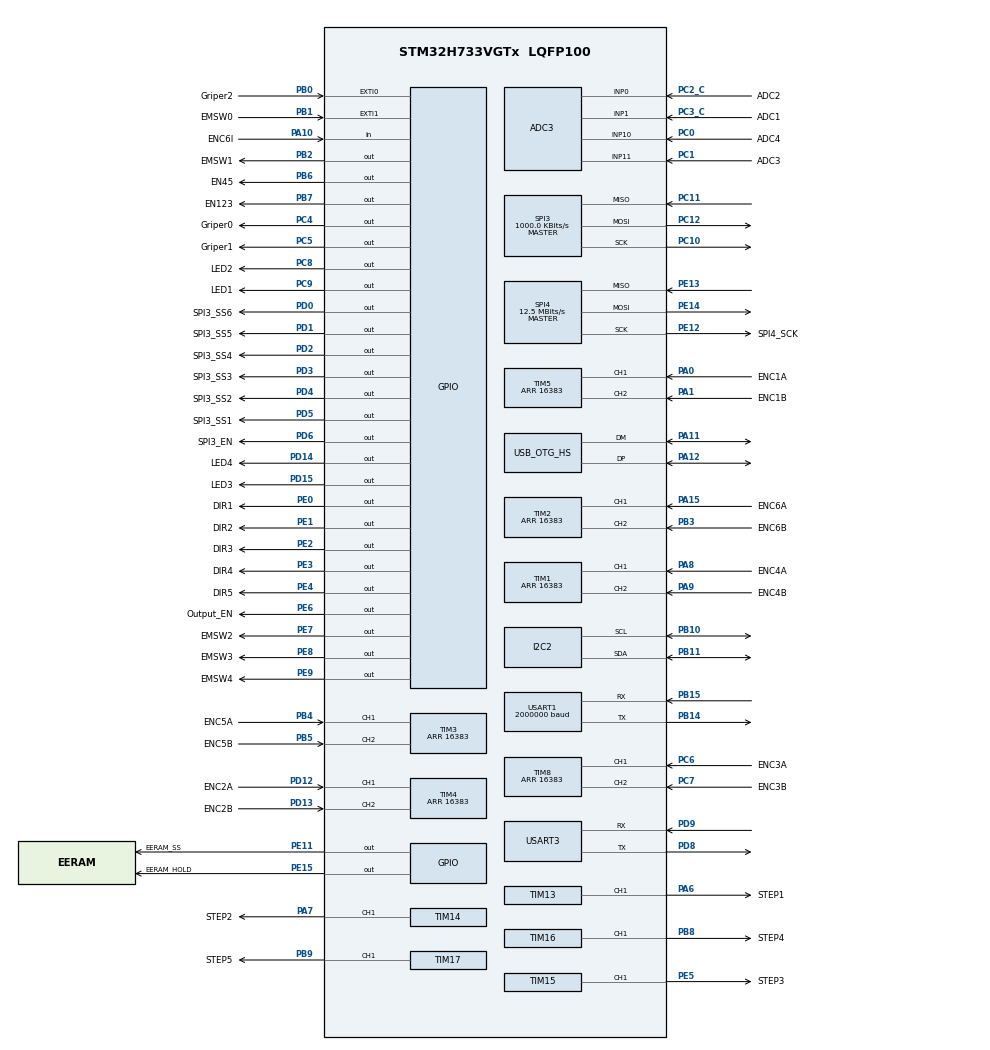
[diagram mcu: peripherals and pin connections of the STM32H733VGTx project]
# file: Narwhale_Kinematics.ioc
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ADC3.Channel-0\#ChannelRegularConversion=ADC_CHANNEL_TEMPSENSOR
ADC3.ClockPrescaler=ADC_CLOCK_ASYNC_DIV6
ADC3.ContinuousConvMode=ENABLE
ADC3.DMAContinuousRequests=DISABLE
ADC3.NbrOfConversion=1
ADC3.NbrOfConversionFlag=1
ADC3.OffsetNumber-0\#ChannelRegularConversion=ADC_OFFSET_NONE
ADC3.OffsetSaturation-0\#ChannelRegularConversion=DISABLE
ADC3.OffsetSign-0\#ChannelRegularConversion=ADC3_OFFSET_SIGN_NEGATIVE
ADC3.OffsetSignedSaturation-0\#ChannelRegularConversion=DISABLE
ADC3.Rank-0\#ChannelRegularConversion=1
ADC3.SamplingTime-0\#ChannelRegularConversion=ADC3_SAMPLETIME_247CYCLES_5
CRC.CRCLength=CRC_POLYLENGTH_8B
CRC.DefaultInitValueUse=DEFAULT_INIT_VALUE_DISABLE
CRC.DefaultPolynomialUse=DEFAULT_POLYNOMIAL_DISABLE
CRC.GeneratingPolynomial=X4+X3+X2+X0
CRC.InitValue=0xC4
CRC.InputDataFormat=CRC_INPUTDATA_FORMAT_HALFWORDS
Dma.Request0=USART1_RX
Dma.USART1_RX.0.Direction=DMA_PERIPH_TO_MEMORY
Dma.USART1_RX.0.EventEnable=DISABLE
Dma.USART1_RX.0.FIFOMode=DMA_FIFOMODE_DISABLE
Dma.USART1_RX.0.Instance=DMA1_Stream0
Dma.USART1_RX.0.MemDataAlignment=DMA_MDATAALIGN_BYTE
Dma.USART1_RX.0.MemInc=DMA_MINC_ENABLE
Dma.USART1_RX.0.Mode=DMA_CIRCULAR
Dma.USART1_RX.0.PeriphDataAlignment=DMA_PDATAALIGN_BYTE
Dma.USART1_RX.0.PeriphInc=DMA_PINC_DISABLE
Dma.USART1_RX.0.Polarity=HAL_DMAMUX_REQ_GEN_RISING
Dma.USART1_RX.0.Priority=DMA_PRIORITY_LOW
Dma.USART1_RX.0.RequestNumber=1
Dma.USART1_RX.0.SignalID=NONE
Dma.USART1_RX.0.SyncEnable=DISABLE
Dma.USART1_RX.0.SyncPolarity=HAL_DMAMUX_SYNC_NO_EVENT
Dma.USART1_RX.0.SyncRequestNumber=1
Dma.USART1_RX.0.SyncSignalID=NONE
I2C2.Timing=0x60404E72
Mcu.Family=STM32H7
Mcu.Name=STM32H733VGTx
Mcu.Package=LQFP100
NVIC.ADC3_IRQn=true\:0\:0\:false\:false\:true\:true\:true
NVIC.DMA1_Stream0_IRQn=true\:0\:0\:false\:false\:true\:false\:true
NVIC.OTG_HS_IRQn=true\:0\:0\:false\:false\:true\:false\:true
NVIC.PriorityGroup=NVIC_PRIORITYGROUP_4
PA0.GPIO_Label=ENC1A
PA0.Signal=S_TIM5_CH1
PA1.GPIO_Label=ENC1B
PA1.Signal=S_TIM5_CH2
PA10.GPIO_Label=ENC6I
PA10.Signal=GPIO_Input
PA11.Mode=Device_Only_FS
PA11.Signal=USB_OTG_HS_DM
PA12.Mode=Device_Only_FS
PA12.Signal=USB_OTG_HS_DP
PA13(JTMS/SWDIO).Mode=Serial_Wire
PA13(JTMS/SWDIO).Signal=DEBUG_JTMS-SWDIO
PA14(JTCK/SWCLK).Mode=Serial_Wire
PA14(JTCK/SWCLK).Signal=DEBUG_JTCK-SWCLK
PA15(JTDI).GPIO_Label=ENC6A
PA15(JTDI).Signal=S_TIM2_CH1_ETR
PA6.GPIO_Label=STEP1
PA6.Signal=S_TIM13_CH1
PA7.GPIO_Label=STEP2
PA7.Signal=S_TIM14_CH1
PA8.GPIO_Label=ENC4A
PA8.Signal=S_TIM1_CH1
PA9.GPIO_Label=ENC4B
PA9.Signal=S_TIM1_CH2
PB0.GPIO_Label=Griper2
PB0.Signal=GPXTI0
PB1.GPIO_Label=EMSW0
PB1.Signal=GPXTI1
PB10.GPIO_Pu=GPIO_PULLUP
PB10.Mode=I2C
PB10.Signal=I2C2_SCL
PB11.GPIO_Pu=GPIO_PULLUP
PB11.Mode=I2C
PB11.Signal=I2C2_SDA
PB14.Mode=Asynchronous
PB14.Signal=USART1_TX
PB15.Mode=Asynchronous
PB15.Signal=USART1_RX
PB2.GPIO_Label=EMSW1
PB2.Signal=GPIO_Output
PB3(JTDO/TRACESWO).GPIO_Label=ENC6B
PB3(JTDO/TRACESWO).Signal=S_TIM2_CH2
PB4(NJTRST).GPIO_Label=ENC5A
PB4(NJTRST).Signal=S_TIM3_CH1
PB5.GPIO_Label=ENC5B
PB5.Signal=S_TIM3_CH2
PB6.GPIO_Label=EN45
PB6.Signal=GPIO_Output
PB7.GPIO_Label=EN123
PB7.Signal=GPIO_Output
PB8.GPIO_Label=STEP4
PB8.Signal=S_TIM16_CH1
PB9.GPIO_Label=STEP5
PB9.Signal=S_TIM17_CH1
PC0.GPIO_Label=ADC4
PC0.Signal=ADCx_INP10
PC1.GPIO_Label=ADC3
PC1.Signal=ADCx_INP11
PC10.Mode=Full_Duplex_Master
PC10.Signal=SPI3_SCK
PC11.Mode=Full_Duplex_Master
PC11.Signal=SPI3_MISO
PC12.Mode=Full_Duplex_Master
PC12.Signal=SPI3_MOSI
PC2_C.GPIO_Label=ADC2
PC2_C.Mode=IN0-Single-Ended
PC2_C.Signal=ADC3_INP0
PC3_C.GPIO_Label=ADC1
PC3_C.Mode=IN1-Single-Ended
PC3_C.Signal=ADC3_INP1
PC4.GPIO_Label=Griper0
PC4.Signal=GPIO_Output
PC5.GPIO_Label=Griper1
PC5.Signal=GPIO_Output
PC6.GPIO_Label=ENC3A
PC6.Signal=S_TIM8_CH1
PC7.GPIO_Label=ENC3B
PC7.Signal=S_TIM8_CH2
PC8.GPIO_Label=LED2
PC8.PinState=GPIO_PIN_RESET
PC8.Signal=GPIO_Output
PC9.GPIO_Label=LED1
PC9.PinState=GPIO_PIN_RESET
PC9.Signal=GPIO_Output
PD0.GPIO_Label=SPI3_SS6
PD0.PinState=GPIO_PIN_SET
PD0.Signal=GPIO_Output
PD1.GPIO_Label=SPI3_SS5
PD1.PinState=GPIO_PIN_SET
PD1.Signal=GPIO_Output
PD12.GPIO_Label=ENC2A
PD12.Signal=S_TIM4_CH1
PD13.GPIO_Label=ENC2B
PD13.Signal=S_TIM4_CH2
PD14.GPIO_Label=LED4
PD14.Signal=GPIO_Output
PD15.GPIO_Label=LED3
PD15.Signal=GPIO_Output
PD2.GPIO_Label=SPI3_SS4
PD2.PinState=GPIO_PIN_SET
PD2.Signal=GPIO_Output
PD3.GPIO_Label=SPI3_SS3
PD3.PinState=GPIO_PIN_SET
PD3.Signal=GPIO_Output
PD4.GPIO_Label=SPI3_SS2
PD4.PinState=GPIO_PIN_SET
PD4.Signal=GPIO_Output
PD5.GPIO_Label=SPI3_SS1
PD5.PinState=GPIO_PIN_SET
PD5.Signal=GPIO_Output
PD6.GPIO_Label=SPI3_EN
PD6.Signal=GPIO_Output
PD8.Mode=Asynchronous
PD8.Signal=USART3_TX
PD9.Mode=Asynchronous
PD9.Signal=USART3_RX
PE0.GPIO_Label=DIR1
PE0.Signal=GPIO_Output
PE1.GPIO_Label=DIR2
PE1.Signal=GPIO_Output
PE11.GPIO_Label=EERAM_SS
PE11.Signal=GPIO_Output
PE12.GPIO_Label=SPI4_SCK
PE12.Mode=Full_Duplex_Master
PE12.Signal=SPI4_SCK
PE13.Mode=Full_Duplex_Master
PE13.Signal=SPI4_MISO
PE14.Mode=Full_Duplex_Master
PE14.Signal=SPI4_MOSI
PE15.GPIO_Label=EERAM_HOLD
PE15.Signal=GPIO_Output
PE2.GPIO_Label=DIR3
PE2.Signal=GPIO_Output
PE3.GPIO_Label=DIR4
PE3.Signal=GPIO_Output
PE4.GPIO_Label=DIR5
PE4.Signal=GPIO_Output
PE5.GPIO_Label=STEP3
PE5.Signal=S_TIM15_CH1
PE6.GPIO_Label=Output_EN
PE6.Signal=GPIO_Output
PE7.GPIO_Label=EMSW2
PE7.Signal=GPIO_Output
PE8.GPIO_Label=EMSW3
PE8.Signal=GPIO_Output
PE9.GPIO_Label=EMSW4
PE9.Signal=GPIO_Output
PH0-OSC_IN.Mode=HSE-External-Oscillator
PH0-OSC_IN.Signal=RCC_OSC_IN
PH1-OSC_OUT.Mode=HSE-External-Oscillator
PH1-OSC_OUT.Signal=RCC_OSC_OUT
ProjectManager.HeapSize=0x200
ProjectManager.StackSize=0x400
ProjectManager.TargetToolchain=STM32CubeIDE
RCC.ADCFreq_Value=100000000
RCC.APB1Freq_Value=137500000
RCC.APB2Freq_Value=137500000
RCC.APB3Freq_Value=137500000
RCC.APB4Freq_Value=137500000
RCC.CortexFreq_Value=550000000
RCC.D1PPRE=RCC_APB3_DIV2
RCC.D2PPRE1=RCC_APB1_DIV2
RCC.D2PPRE2=RCC_APB2_DIV2
RCC.D3PPRE=RCC_APB4_DIV2
RCC.DIVM1=2
RCC.DIVM2=2
RCC.DIVM3=25
RCC.DIVN1=44
RCC.DIVN2=16
RCC.DIVN3=256
RCC.DIVP1=1
RCC.HCLKFreq_Value=275000000
RCC.HPRE=RCC_HCLK_DIV2
RCC.LockedElements=D1CPREOutput
RCC.PLL1_VCI_Range-AdvancedSettings=RCC_PLL1VCIRANGE_0
RCC.PLL1_VCO_SEL-AdvancedSettings=RCC_PLL1VCOWIDE
RCC.PLL2_VCI_Range-AdvancedSettings=RCC_PLL2VCIRANGE_0
RCC.PLL2_VCO_SEL-AdvancedSettings=RCC_PLL2VCOMEDIUM
RCC.PLL3_VCI_Range-AdvancedSettings=RCC_PLL3VCIRANGE_3
RCC.PLL3_VCO_SEL-AdvancedSettings=RCC_PLL3VCOWIDE
RCC.PLLSourceVirtual=RCC_PLLSOURCE_HSE
RCC.SPI123CLockSelection=RCC_SPI123CLKSOURCE_PLL3
RCC.SYSCLKFreq_VALUE=550000000
RCC.SYSCLKSource=RCC_SYSCLKSOURCE_PLLCLK
RCC.Spi45ClockSelection=RCC_SPI45CLKSOURCE_PLL2
RCC.USART16CLockSelection=RCC_USART16910CLKSOURCE_PLL2
RCC.USART234578CLockSelection=RCC_USART234578CLKSOURCE_PLL2
RCC.USBCLockSelection=RCC_USBCLKSOURCE_HSI48
RCC.USBFreq_Value=48000000
SH.ADCx_INP10.0=ADC3_INP10,IN10-Single-Ended
SH.ADCx_INP11.0=ADC3_INP11,IN11-Single-Ended
SH.S_TIM13_CH1.0=TIM13_CH1,PWM Generation1 CH1
SH.S_TIM14_CH1.0=TIM14_CH1,PWM Generation1 CH1
SH.S_TIM15_CH1.0=TIM15_CH1,PWM Generation1 CH1
SH.S_TIM16_CH1.0=TIM16_CH1,PWM Generation1 CH1
SH.S_TIM17_CH1.0=TIM17_CH1,PWM Generation1 CH1
SH.S_TIM1_CH1.0=TIM1_CH1,Encoder_Interface
SH.S_TIM1_CH2.0=TIM1_CH2,Encoder_Interface
SH.S_TIM2_CH1_ETR.0=TIM2_CH1,Encoder_Interface
SH.S_TIM2_CH2.0=TIM2_CH2,Encoder_Interface
SH.S_TIM3_CH1.0=TIM3_CH1,Encoder_Interface
SH.S_TIM3_CH2.0=TIM3_CH2,Encoder_Interface
SH.S_TIM4_CH1.0=TIM4_CH1,Encoder_Interface
SH.S_TIM4_CH2.0=TIM4_CH2,Encoder_Interface
SH.S_TIM5_CH1.0=TIM5_CH1,Encoder_Interface
SH.S_TIM5_CH2.0=TIM5_CH2,Encoder_Interface
SH.S_TIM8_CH1.0=TIM8_CH1,Encoder_Interface
SH.S_TIM8_CH2.0=TIM8_CH2,Encoder_Interface
SPI3.BaudRatePrescaler=SPI_BAUDRATEPRESCALER_128
SPI3.CLKPhase=SPI_PHASE_2EDGE
SPI3.CRCCalculation=SPI_CRCCALCULATION_DISABLE
SPI3.CRCPolynomial=0x1D
SPI3.CalculateBaudRate=1000.0 KBits/s
SPI3.DataSize=SPI_DATASIZE_8BIT
SPI3.Direction=SPI_DIRECTION_2LINES
SPI3.FirstBit=SPI_FIRSTBIT_MSB
SPI3.Mode=SPI_MODE_MASTER
SPI3.VirtualType=VM_MASTER
SPI4.BaudRatePrescaler=SPI_BAUDRATEPRESCALER_8
SPI4.CalculateBaudRate=12.5 MBits/s
SPI4.DataSize=SPI_DATASIZE_16BIT
SPI4.Direction=SPI_DIRECTION_2LINES
SPI4.Mode=SPI_MODE_MASTER
SPI4.VirtualType=VM_MASTER
TIM1.AutoReloadPreload=TIM_AUTORELOAD_PRELOAD_ENABLE
TIM1.EncoderMode=TIM_ENCODERMODE_TI12
TIM1.IC1Filter=0
TIM1.IC2Filter=0
TIM1.Period=16383
TIM13.Channel=TIM_CHANNEL_1
TIM13.Period=1000-1
TIM13.Prescaler=275-1
TIM13.Pulse=500-1
TIM14.Channel=TIM_CHANNEL_1
TIM14.Period=1000-1
TIM14.Prescaler=275-1
TIM14.Pulse=500-1
TIM15.Channel-PWM\ Generation1\ CH1=TIM_CHANNEL_1
TIM15.Period=20000-1
TIM15.Prescaler=275-1
TIM15.Pulse-PWM\ Generation1\ CH1=2000-1
TIM16.Channel=TIM_CHANNEL_1
TIM16.Period=1000-1
TIM16.Prescaler=275-1
TIM16.Pulse=500-1
TIM17.Channel=TIM_CHANNEL_1
TIM17.Period=1000-1
TIM17.Prescaler=275-1
TIM17.Pulse=500-1
TIM2.AutoReloadPreload=TIM_AUTORELOAD_PRELOAD_ENABLE
TIM2.EncoderMode=TIM_ENCODERMODE_TI12
TIM2.IC1Filter=0
TIM2.IC2Filter=0
TIM2.Period=16383
TIM23.Prescaler=275-1
TIM24.Prescaler=275-1
TIM3.AutoReloadPreload=TIM_AUTORELOAD_PRELOAD_ENABLE
TIM3.EncoderMode=TIM_ENCODERMODE_TI12
TIM3.IC1Filter=0
TIM3.IC2Filter=10
TIM3.Period=16383
TIM4.AutoReloadPreload=TIM_AUTORELOAD_PRELOAD_ENABLE
TIM4.EncoderMode=TIM_ENCODERMODE_TI12
TIM4.IC1Filter=0
TIM4.IC2Filter=0
TIM4.Period=16383
TIM5.AutoReloadPreload=TIM_AUTORELOAD_PRELOAD_ENABLE
TIM5.EncoderMode=TIM_ENCODERMODE_TI12
TIM5.IC1Filter=0
TIM5.IC2Filter=0
TIM5.Period=16383
TIM5.TIM_MasterOutputTrigger=TIM_TRGO_RESET
TIM6.Prescaler=275-1
TIM8.AutoReloadPreload=TIM_AUTORELOAD_PRELOAD_ENABLE
TIM8.EncoderMode=TIM_ENCODERMODE_TI12
TIM8.IC1Filter=0
TIM8.IC2Filter=0
TIM8.Period=16383
USART1.BaudRate=2000000
USART1.SwapParam=ADVFEATURE_SWAP_DISABLE
USART1.VirtualMode-Asynchronous=VM_ASYNC
USART3.VirtualMode-Asynchronous=VM_ASYNC
USB_DEVICE.CLASS_NAME_HS=CDC
USB_DEVICE.VirtualMode=Cdc
USB_DEVICE.VirtualModeHS=Cdc_HS
USB_OTG_HS.VirtualMode-Device_Only_FS=Device_Only_FS
VP_ADC3_TempSens_Input.Mode=IN-TempSens
VP_ADC3_Vbat_Input.Mode=IN-Vbat
VP_CRC_VS_CRC.Mode=CRC_Activate
VP_TIM13_VS_ClockSourceINT.Mode=Enable_Timer
VP_TIM14_VS_ClockSourceINT.Mode=Enable_Timer
VP_TIM16_VS_ClockSourceINT.Mode=Enable_Timer
VP_TIM17_VS_ClockSourceINT.Mode=Enable_Timer
VP_TIM23_VS_ClockSourceINT.Mode=Internal
VP_TIM24_VS_ClockSourceINT.Mode=Internal
VP_TIM6_VS_ClockSourceINT.Mode=Enable_Timer
VP_USB_DEVICE_VS_USB_DEVICE_CDC_HS.Mode=CDC_HS
board=custom

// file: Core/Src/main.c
/* USER CODE BEGIN Header */
/**
  ******************************************************************************
  * @file           : main.c
  * @brief          : Main program body
  ******************************************************************************
  * @attention
  *
  * Copyright (c) 2022 STMicroelectronics.
  * All rights reserved.
  *
  * This software is licensed under terms that can be found in the LICENSE file
  * in the root directory of this software component.
  * If no LICENSE file comes with this software, it is provided AS-IS.
  *
  ******************************************************************************
  */
/* USER CODE END Header */
#include "main.h"
#include "usb_device.h"
#include "kinematics.h"

/* USER CODE BEGIN PD */
//	float v_x[2] = {400.01,500};
//	float v_y[2]= {0,0};
//	float v_z[2] = {420.99,260};
//	float v_pitch[2] = {-3.1416,-3.1416};
//	float v_yaw[2] = {3.1416,3.1416};
	float q[5]={0,-0.6975,0.5554,0.1421,0};
	float qv[5];
	float v_x, v_y, v_z, v_pitch, v_yaw;

/* USER CODE END PD */

ADC_HandleTypeDef hadc3;

CRC_HandleTypeDef hcrc;

I2C_HandleTypeDef hi2c2;

SPI_HandleTypeDef hspi3;
SPI_HandleTypeDef hspi4;

TIM_HandleTypeDef htim1;
TIM_HandleTypeDef htim2;
TIM_HandleTypeDef htim3;
TIM_HandleTypeDef htim4;
TIM_HandleTypeDef htim5;
TIM_HandleTypeDef htim6;
TIM_HandleTypeDef htim8;
TIM_HandleTypeDef htim13;
TIM_HandleTypeDef htim14;
TIM_HandleTypeDef htim15;
TIM_HandleTypeDef htim16;
TIM_HandleTypeDef htim17;
TIM_HandleTypeDef htim23;
TIM_HandleTypeDef htim24;

UART_HandleTypeDef huart1;
UART_HandleTypeDef huart3;
DMA_HandleTypeDef hdma_usart1_rx;

void SystemClock_Config(void);
void PeriphCommonClock_Config(void);
static void MX_GPIO_Init(void);
static void MX_DMA_Init(void);
static void MX_ADC3_Init(void);
static void MX_TIM1_Init(void);
static void MX_TIM3_Init(void);
static void MX_TIM4_Init(void);
static void MX_TIM5_Init(void);
static void MX_TIM8_Init(void);
static void MX_TIM13_Init(void);
static void MX_TIM14_Init(void);
static void MX_TIM15_Init(void);
static void MX_TIM16_Init(void);
static void MX_TIM17_Init(void);
static void MX_USART1_UART_Init(void);
static void MX_USART3_UART_Init(void);
static void MX_SPI3_Init(void);
static void MX_SPI4_Init(void);
static void MX_TIM2_Init(void);
static void MX_I2C2_Init(void);
static void MX_CRC_Init(void);
static void MX_TIM24_Init(void);
static void MX_TIM23_Init(void);
static void MX_TIM6_Init(void);

int main(void)
{
  /* USER CODE BEGIN 1 */
	uint32_t timer1;
	v_x = 0.000023997;
	v_y = 0;
	v_z = -0.000038637;
	v_pitch = 0;
	v_yaw = 0;

  /* USER CODE END 1 */

  /* MCU Configuration--------------------------------------------------------*/

  /* Reset of all peripherals, Initializes the Flash interface and the Systick. */
  HAL_Init();

  /* Configure the system clock */
  SystemClock_Config();

/* Configure the peripherals common clocks */
  PeriphCommonClock_Config();

  /* Initialize all configured peripherals */
  MX_GPIO_Init();
  MX_DMA_Init();
  MX_ADC3_Init();
  MX_TIM1_Init();
  MX_TIM3_Init();
  MX_TIM4_Init();
  MX_TIM5_Init();
  MX_TIM8_Init();
  MX_TIM13_Init();
  MX_TIM14_Init();
  MX_TIM15_Init();
  MX_TIM16_Init();
  MX_TIM17_Init();
  MX_USART1_UART_Init();
  MX_USART3_UART_Init();
  MX_SPI3_Init();
  MX_SPI4_Init();
  MX_TIM2_Init();
  MX_I2C2_Init();
  MX_CRC_Init();
  MX_USB_DEVICE_Init();
  MX_TIM24_Init();
  MX_TIM23_Init();
  MX_TIM6_Init();

  /* Infinite loop */
	while (1) {

    /* USER CODE BEGIN 3 */
//		if (HAL_GetTick() - timer1 > 1000) { gettick จะนับไปเรื่อย
//			timer1 = HAL_GetTick(); keep count ตอนนั้นไว้ที่ timer1
//			HAL_GPIO_TogglePin(GPIOC, GPIO_PIN_9);
//		}
//		float a = cos(3.14);
		IVK(v_x, v_y, v_z, v_pitch, v_yaw, q, qv);

  }
  /* USER CODE END 3 */
}

void SystemClock_Config(void)
{
  RCC_OscInitTypeDef RCC_OscInitStruct = {0};
  RCC_ClkInitTypeDef RCC_ClkInitStruct = {0};

  /** Supply configuration update enable
  */
  HAL_PWREx_ConfigSupply(PWR_LDO_SUPPLY);
  /** Configure the main internal regulator output voltage
  */
  __HAL_PWR_VOLTAGESCALING_CONFIG(PWR_REGULATOR_VOLTAGE_SCALE0);

  while(!__HAL_PWR_GET_FLAG(PWR_FLAG_VOSRDY)) {}
  /** Macro to configure the PLL clock source
  */
  __HAL_RCC_PLL_PLLSOURCE_CONFIG(RCC_PLLSOURCE_HSE);
  /** Initializes the RCC Oscillators according to the specified parameters
  * in the RCC_OscInitTypeDef structure.
  */
  RCC_OscInitStruct.OscillatorType = RCC_OSCILLATORTYPE_HSI48|RCC_OSCILLATORTYPE_HSE;
  RCC_OscInitStruct.HSEState = RCC_HSE_ON;
  RCC_OscInitStruct.HSI48State = RCC_HSI48_ON;
  RCC_OscInitStruct.PLL.PLLState = RCC_PLL_ON;
  RCC_OscInitStruct.PLL.PLLSource = RCC_PLLSOURCE_HSE;
  RCC_OscInitStruct.PLL.PLLM = 2;
  RCC_OscInitStruct.PLL.PLLN = 44;
  RCC_OscInitStruct.PLL.PLLP = 1;
  RCC_OscInitStruct.PLL.PLLQ = 2;
  RCC_OscInitStruct.PLL.PLLR = 2;
  RCC_OscInitStruct.PLL.PLLRGE = RCC_PLL1VCIRANGE_3;
  RCC_OscInitStruct.PLL.PLLVCOSEL = RCC_PLL1VCOWIDE;
  RCC_OscInitStruct.PLL.PLLFRACN = 0;
  if (HAL_RCC_OscConfig(&RCC_OscInitStruct) != HAL_OK)
  {
    Error_Handler();
  }
  /** Initializes the CPU, AHB and APB buses clocks
  */
  RCC_ClkInitStruct.ClockType = RCC_CLOCKTYPE_HCLK|RCC_CLOCKTYPE_SYSCLK
                              |RCC_CLOCKTYPE_PCLK1|RCC_CLOCKTYPE_PCLK2
                              |RCC_CLOCKTYPE_D3PCLK1|RCC_CLOCKTYPE_D1PCLK1;
  RCC_ClkInitStruct.SYSCLKSource = RCC_SYSCLKSOURCE_PLLCLK;
  RCC_ClkInitStruct.SYSCLKDivider = RCC_SYSCLK_DIV1;
  RCC_ClkInitStruct.AHBCLKDivider = RCC_HCLK_DIV2;
  RCC_ClkInitStruct.APB3CLKDivider = RCC_APB3_DIV2;
  RCC_ClkInitStruct.APB1CLKDivider = RCC_APB1_DIV2;
  RCC_ClkInitStruct.APB2CLKDivider = RCC_APB2_DIV2;
  RCC_ClkInitStruct.APB4CLKDivider = RCC_APB4_DIV2;

  if (HAL_RCC_ClockConfig(&RCC_ClkInitStruct, FLASH_LATENCY_3) != HAL_OK)
  {
    Error_Handler();
  }
}

void PeriphCommonClock_Config(void)
{
  RCC_PeriphCLKInitTypeDef PeriphClkInitStruct = {0};

  /** Initializes the peripherals clock
  */
  PeriphClkInitStruct.PeriphClockSelection = RCC_PERIPHCLK_ADC|RCC_PERIPHCLK_SPI4
                              |RCC_PERIPHCLK_USART1|RCC_PERIPHCLK_USART3;
  PeriphClkInitStruct.PLL2.PLL2M = 2;
  PeriphClkInitStruct.PLL2.PLL2N = 16;
  PeriphClkInitStruct.PLL2.PLL2P = 2;
  PeriphClkInitStruct.PLL2.PLL2Q = 2;
  PeriphClkInitStruct.PLL2.PLL2R = 2;
  PeriphClkInitStruct.PLL2.PLL2RGE = RCC_PLL2VCIRANGE_3;
  PeriphClkInitStruct.PLL2.PLL2VCOSEL = RCC_PLL2VCOWIDE;
  PeriphClkInitStruct.PLL2.PLL2FRACN = 0;
  PeriphClkInitStruct.Spi45ClockSelection = RCC_SPI45CLKSOURCE_PLL2;
  PeriphClkInitStruct.Usart234578ClockSelection = RCC_USART234578CLKSOURCE_PLL2;
  PeriphClkInitStruct.Usart16ClockSelection = RCC_USART16910CLKSOURCE_PLL2;
  PeriphClkInitStruct.AdcClockSelection = RCC_ADCCLKSOURCE_PLL2;
  if (HAL_RCCEx_PeriphCLKConfig(&PeriphClkInitStruct) != HAL_OK)
  {
    Error_Handler();
  }
}

static void MX_ADC3_Init(void)
{

  ADC_ChannelConfTypeDef sConfig = {0};

  /** Common config
  */
  hadc3.Instance = ADC3;
  hadc3.Init.ClockPrescaler = ADC_CLOCK_ASYNC_DIV6;
  hadc3.Init.DataAlign = ADC3_DATAALIGN_RIGHT;
  hadc3.Init.ScanConvMode = ADC_SCAN_DISABLE;
  hadc3.Init.EOCSelection = ADC_EOC_SINGLE_CONV;
  hadc3.Init.LowPowerAutoWait = DISABLE;
  hadc3.Init.ContinuousConvMode = ENABLE;
  hadc3.Init.NbrOfConversion = 1;
  hadc3.Init.DiscontinuousConvMode = DISABLE;
  hadc3.Init.ExternalTrigConv = ADC_SOFTWARE_START;
  hadc3.Init.ExternalTrigConvEdge = ADC_EXTERNALTRIGCONVEDGE_NONE;
  hadc3.Init.DMAContinuousRequests = DISABLE;
  hadc3.Init.SamplingMode = ADC_SAMPLING_MODE_NORMAL;
  hadc3.Init.ConversionDataManagement = ADC_CONVERSIONDATA_DR;
  hadc3.Init.Overrun = ADC_OVR_DATA_PRESERVED;
  hadc3.Init.LeftBitShift = ADC_LEFTBITSHIFT_NONE;
  hadc3.Init.OversamplingMode = DISABLE;
  if (HAL_ADC_Init(&hadc3) != HAL_OK)
  {
    Error_Handler();
  }
  /** Configure Regular Channel
  */
  sConfig.Channel = ADC_CHANNEL_TEMPSENSOR;
  sConfig.Rank = ADC_REGULAR_RANK_1;
  sConfig.SamplingTime = ADC3_SAMPLETIME_247CYCLES_5;
  sConfig.SingleDiff = ADC_SINGLE_ENDED;
  sConfig.OffsetNumber = ADC_OFFSET_NONE;
  sConfig.Offset = 0;
  sConfig.OffsetSignedSaturation = DISABLE;
  sConfig.OffsetSign = ADC3_OFFSET_SIGN_NEGATIVE;
  sConfig.OffsetSaturation = DISABLE;
  if (HAL_ADC_ConfigChannel(&hadc3, &sConfig) != HAL_OK)
  {
    Error_Handler();
  }

}

static void MX_CRC_Init(void)
{

  hcrc.Instance = CRC;
  hcrc.Init.DefaultPolynomialUse = DEFAULT_POLYNOMIAL_DISABLE;
  hcrc.Init.DefaultInitValueUse = DEFAULT_INIT_VALUE_DISABLE;
  hcrc.Init.GeneratingPolynomial = 29;
  hcrc.Init.CRCLength = CRC_POLYLENGTH_8B;
  hcrc.Init.InitValue = 0xC4;
  hcrc.Init.InputDataInversionMode = CRC_INPUTDATA_INVERSION_NONE;
  hcrc.Init.OutputDataInversionMode = CRC_OUTPUTDATA_INVERSION_DISABLE;
  hcrc.InputDataFormat = CRC_INPUTDATA_FORMAT_HALFWORDS;
  if (HAL_CRC_Init(&hcrc) != HAL_OK)
  {
    Error_Handler();
  }

}

static void MX_I2C2_Init(void)
{

  hi2c2.Instance = I2C2;
  hi2c2.Init.Timing = 0x60404E72;
  hi2c2.Init.OwnAddress1 = 0;
  hi2c2.Init.AddressingMode = I2C_ADDRESSINGMODE_7BIT;
  hi2c2.Init.DualAddressMode = I2C_DUALADDRESS_DISABLE;
  hi2c2.Init.OwnAddress2 = 0;
  hi2c2.Init.OwnAddress2Masks = I2C_OA2_NOMASK;
  hi2c2.Init.GeneralCallMode = I2C_GENERALCALL_DISABLE;
  hi2c2.Init.NoStretchMode = I2C_NOSTRETCH_DISABLE;
  if (HAL_I2C_Init(&hi2c2) != HAL_OK)
  {
    Error_Handler();
  }
  /** Configure Analogue filter
  */
  if (HAL_I2CEx_ConfigAnalogFilter(&hi2c2, I2C_ANALOGFILTER_ENABLE) != HAL_OK)
  {
    Error_Handler();
  }
  /** Configure Digital filter
  */
  if (HAL_I2CEx_ConfigDigitalFilter(&hi2c2, 0) != HAL_OK)
  {
    Error_Handler();
  }

}

static void MX_SPI3_Init(void)
{

  /* SPI3 parameter configuration*/
  hspi3.Instance = SPI3;
  hspi3.Init.Mode = SPI_MODE_MASTER;
  hspi3.Init.Direction = SPI_DIRECTION_2LINES;
  hspi3.Init.DataSize = SPI_DATASIZE_8BIT;
  hspi3.Init.CLKPolarity = SPI_POLARITY_LOW;
  hspi3.Init.CLKPhase = SPI_PHASE_2EDGE;
  hspi3.Init.NSS = SPI_NSS_SOFT;
  hspi3.Init.BaudRatePrescaler = SPI_BAUDRATEPRESCALER_128;
  hspi3.Init.FirstBit = SPI_FIRSTBIT_MSB;
  hspi3.Init.TIMode = SPI_TIMODE_DISABLE;
  hspi3.Init.CRCCalculation = SPI_CRCCALCULATION_DISABLE;
  hspi3.Init.CRCPolynomial = 0x1D;
  hspi3.Init.NSSPMode = SPI_NSS_PULSE_ENABLE;
  hspi3.Init.NSSPolarity = SPI_NSS_POLARITY_LOW;
  hspi3.Init.FifoThreshold = SPI_FIFO_THRESHOLD_01DATA;
  hspi3.Init.TxCRCInitializationPattern = SPI_CRC_INITIALIZATION_ALL_ZERO_PATTERN;
  hspi3.Init.RxCRCInitializationPattern = SPI_CRC_INITIALIZATION_ALL_ZERO_PATTERN;
  hspi3.Init.MasterSSIdleness = SPI_MASTER_SS_IDLENESS_00CYCLE;
  hspi3.Init.MasterInterDataIdleness = SPI_MASTER_INTERDATA_IDLENESS_00CYCLE;
  hspi3.Init.MasterReceiverAutoSusp = SPI_MASTER_RX_AUTOSUSP_DISABLE;
  hspi3.Init.MasterKeepIOState = SPI_MASTER_KEEP_IO_STATE_DISABLE;
  hspi3.Init.IOSwap = SPI_IO_SWAP_DISABLE;
  if (HAL_SPI_Init(&hspi3) != HAL_OK)
  {
    Error_Handler();
  }

}

static void MX_SPI4_Init(void)
{

  /* SPI4 parameter configuration*/
  hspi4.Instance = SPI4;
  hspi4.Init.Mode = SPI_MODE_MASTER;
  hspi4.Init.Direction = SPI_DIRECTION_2LINES;
  hspi4.Init.DataSize = SPI_DATASIZE_16BIT;
  hspi4.Init.CLKPolarity = SPI_POLARITY_LOW;
  hspi4.Init.CLKPhase = SPI_PHASE_1EDGE;
  hspi4.Init.NSS = SPI_NSS_SOFT;
  hspi4.Init.BaudRatePrescaler = SPI_BAUDRATEPRESCALER_8;
  hspi4.Init.FirstBit = SPI_FIRSTBIT_MSB;
  hspi4.Init.TIMode = SPI_TIMODE_DISABLE;
  hspi4.Init.CRCCalculation = SPI_CRCCALCULATION_DISABLE;
  hspi4.Init.CRCPolynomial = 0x0;
  hspi4.Init.NSSPMode = SPI_NSS_PULSE_ENABLE;
  hspi4.Init.NSSPolarity = SPI_NSS_POLARITY_LOW;
  hspi4.Init.FifoThreshold = SPI_FIFO_THRESHOLD_01DATA;
  hspi4.Init.TxCRCInitializationPattern = SPI_CRC_INITIALIZATION_ALL_ZERO_PATTERN;
  hspi4.Init.RxCRCInitializationPattern = SPI_CRC_INITIALIZATION_ALL_ZERO_PATTERN;
  hspi4.Init.MasterSSIdleness = SPI_MASTER_SS_IDLENESS_00CYCLE;
  hspi4.Init.MasterInterDataIdleness = SPI_MASTER_INTERDATA_IDLENESS_00CYCLE;
  hspi4.Init.MasterReceiverAutoSusp = SPI_MASTER_RX_AUTOSUSP_DISABLE;
  hspi4.Init.MasterKeepIOState = SPI_MASTER_KEEP_IO_STATE_DISABLE;
  hspi4.Init.IOSwap = SPI_IO_SWAP_DISABLE;
  if (HAL_SPI_Init(&hspi4) != HAL_OK)
  {
    Error_Handler();
  }

}

static void MX_TIM1_Init(void)
{

  TIM_Encoder_InitTypeDef sConfig = {0};
  TIM_MasterConfigTypeDef sMasterConfig = {0};

  htim1.Instance = TIM1;
  htim1.Init.Prescaler = 0;
  htim1.Init.CounterMode = TIM_COUNTERMODE_UP;
  htim1.Init.Period = 16383;
  htim1.Init.ClockDivision = TIM_CLOCKDIVISION_DIV1;
  htim1.Init.RepetitionCounter = 0;
  htim1.Init.AutoReloadPreload = TIM_AUTORELOAD_PRELOAD_ENABLE;
  sConfig.EncoderMode = TIM_ENCODERMODE_TI12;
  sConfig.IC1Polarity = TIM_ICPOLARITY_RISING;
  sConfig.IC1Selection = TIM_ICSELECTION_DIRECTTI;
  sConfig.IC1Prescaler = TIM_ICPSC_DIV1;
  sConfig.IC1Filter = 0;
  sConfig.IC2Polarity = TIM_ICPOLARITY_RISING;
  sConfig.IC2Selection = TIM_ICSELECTION_DIRECTTI;
  sConfig.IC2Prescaler = TIM_ICPSC_DIV1;
  sConfig.IC2Filter = 0;
  if (HAL_TIM_Encoder_Init(&htim1, &sConfig) != HAL_OK)
  {
    Error_Handler();
  }
  sMasterConfig.MasterOutputTrigger = TIM_TRGO_RESET;
  sMasterConfig.MasterOutputTrigger2 = TIM_TRGO2_RESET;
  sMasterConfig.MasterSlaveMode = TIM_MASTERSLAVEMODE_DISABLE;
  if (HAL_TIMEx_MasterConfigSynchronization(&htim1, &sMasterConfig) != HAL_OK)
  {
    Error_Handler();
  }

}

static void MX_TIM2_Init(void)
{

  TIM_Encoder_InitTypeDef sConfig = {0};
  TIM_MasterConfigTypeDef sMasterConfig = {0};

  htim2.Instance = TIM2;
  htim2.Init.Prescaler = 0;
  htim2.Init.CounterMode = TIM_COUNTERMODE_UP;
  htim2.Init.Period = 16383;
  htim2.Init.ClockDivision = TIM_CLOCKDIVISION_DIV1;
  htim2.Init.AutoReloadPreload = TIM_AUTORELOAD_PRELOAD_ENABLE;
  sConfig.EncoderMode = TIM_ENCODERMODE_TI12;
  sConfig.IC1Polarity = TIM_ICPOLARITY_RISING;
  sConfig.IC1Selection = TIM_ICSELECTION_DIRECTTI;
  sConfig.IC1Prescaler = TIM_ICPSC_DIV1;
  sConfig.IC1Filter = 0;
  sConfig.IC2Polarity = TIM_ICPOLARITY_RISING;
  sConfig.IC2Selection = TIM_ICSELECTION_DIRECTTI;
  sConfig.IC2Prescaler = TIM_ICPSC_DIV1;
  sConfig.IC2Filter = 0;
  if (HAL_TIM_Encoder_Init(&htim2, &sConfig) != HAL_OK)
  {
    Error_Handler();
  }
  sMasterConfig.MasterOutputTrigger = TIM_TRGO_RESET;
  sMasterConfig.MasterSlaveMode = TIM_MASTERSLAVEMODE_DISABLE;
  if (HAL_TIMEx_MasterConfigSynchronization(&htim2, &sMasterConfig) != HAL_OK)
  {
    Error_Handler();
  }

}

static void MX_TIM3_Init(void)
{

  TIM_Encoder_InitTypeDef sConfig = {0};
  TIM_MasterConfigTypeDef sMasterConfig = {0};

  htim3.Instance = TIM3;
  htim3.Init.Prescaler = 0;
  htim3.Init.CounterMode = TIM_COUNTERMODE_UP;
  htim3.Init.Period = 16383;
  htim3.Init.ClockDivision = TIM_CLOCKDIVISION_DIV1;
  htim3.Init.AutoReloadPreload = TIM_AUTORELOAD_PRELOAD_ENABLE;
  sConfig.EncoderMode = TIM_ENCODERMODE_TI12;
  sConfig.IC1Polarity = TIM_ICPOLARITY_RISING;
  sConfig.IC1Selection = TIM_ICSELECTION_DIRECTTI;
  sConfig.IC1Prescaler = TIM_ICPSC_DIV1;
  sConfig.IC1Filter = 0;
  sConfig.IC2Polarity = TIM_ICPOLARITY_RISING;
  sConfig.IC2Selection = TIM_ICSELECTION_DIRECTTI;
  sConfig.IC2Prescaler = TIM_ICPSC_DIV1;
  sConfig.IC2Filter = 10;
  if (HAL_TIM_Encoder_Init(&htim3, &sConfig) != HAL_OK)
  {
    Error_Handler();
  }
  sMasterConfig.MasterOutputTrigger = TIM_TRGO_RESET;
  sMasterConfig.MasterSlaveMode = TIM_MASTERSLAVEMODE_DISABLE;
  if (HAL_TIMEx_MasterConfigSynchronization(&htim3, &sMasterConfig) != HAL_OK)
  {
    Error_Handler();
  }

}

static void MX_TIM4_Init(void)
{

  TIM_Encoder_InitTypeDef sConfig = {0};
  TIM_MasterConfigTypeDef sMasterConfig = {0};

  htim4.Instance = TIM4;
  htim4.Init.Prescaler = 0;
  htim4.Init.CounterMode = TIM_COUNTERMODE_UP;
  htim4.Init.Period = 16383;
  htim4.Init.ClockDivision = TIM_CLOCKDIVISION_DIV1;
  htim4.Init.AutoReloadPreload = TIM_AUTORELOAD_PRELOAD_ENABLE;
  sConfig.EncoderMode = TIM_ENCODERMODE_TI12;
  sConfig.IC1Polarity = TIM_ICPOLARITY_RISING;
  sConfig.IC1Selection = TIM_ICSELECTION_DIRECTTI;
  sConfig.IC1Prescaler = TIM_ICPSC_DIV1;
  sConfig.IC1Filter = 0;
  sConfig.IC2Polarity = TIM_ICPOLARITY_RISING;
  sConfig.IC2Selection = TIM_ICSELECTION_DIRECTTI;
  sConfig.IC2Prescaler = TIM_ICPSC_DIV1;
  sConfig.IC2Filter = 0;
  if (HAL_TIM_Encoder_Init(&htim4, &sConfig) != HAL_OK)
  {
    Error_Handler();
  }
  sMasterConfig.MasterOutputTrigger = TIM_TRGO_RESET;
  sMasterConfig.MasterSlaveMode = TIM_MASTERSLAVEMODE_DISABLE;
  if (HAL_TIMEx_MasterConfigSynchronization(&htim4, &sMasterConfig) != HAL_OK)
  {
    Error_Handler();
  }

}

static void MX_TIM5_Init(void)
{

  TIM_Encoder_InitTypeDef sConfig = {0};
  TIM_MasterConfigTypeDef sMasterConfig = {0};

  htim5.Instance = TIM5;
  htim5.Init.Prescaler = 0;
  htim5.Init.CounterMode = TIM_COUNTERMODE_UP;
  htim5.Init.Period = 16383;
  htim5.Init.ClockDivision = TIM_CLOCKDIVISION_DIV1;
  htim5.Init.AutoReloadPreload = TIM_AUTORELOAD_PRELOAD_ENABLE;
  sConfig.EncoderMode = TIM_ENCODERMODE_TI12;
  sConfig.IC1Polarity = TIM_ICPOLARITY_RISING;
  sConfig.IC1Selection = TIM_ICSELECTION_DIRECTTI;
  sConfig.IC1Prescaler = TIM_ICPSC_DIV1;
  sConfig.IC1Filter = 0;
  sConfig.IC2Polarity = TIM_ICPOLARITY_RISING;
  sConfig.IC2Selection = TIM_ICSELECTION_DIRECTTI;
  sConfig.IC2Prescaler = TIM_ICPSC_DIV1;
  sConfig.IC2Filter = 0;
  if (HAL_TIM_Encoder_Init(&htim5, &sConfig) != HAL_OK)
  {
    Error_Handler();
  }
  sMasterConfig.MasterOutputTrigger = TIM_TRGO_RESET;
  sMasterConfig.MasterSlaveMode = TIM_MASTERSLAVEMODE_DISABLE;
  if (HAL_TIMEx_MasterConfigSynchronization(&htim5, &sMasterConfig) != HAL_OK)
  {
    Error_Handler();
  }

}

static void MX_TIM6_Init(void)
{

  TIM_MasterConfigTypeDef sMasterConfig = {0};

  htim6.Instance = TIM6;
  htim6.Init.Prescaler = 275-1;
  htim6.Init.CounterMode = TIM_COUNTERMODE_UP;
  htim6.Init.Period = 65535;
  htim6.Init.AutoReloadPreload = TIM_AUTORELOAD_PRELOAD_DISABLE;
  if (HAL_TIM_Base_Init(&htim6) != HAL_OK)
  {
    Error_Handler();
  }
  sMasterConfig.MasterOutputTrigger = TIM_TRGO_RESET;
  sMasterConfig.MasterSlaveMode = TIM_MASTERSLAVEMODE_DISABLE;
  if (HAL_TIMEx_MasterConfigSynchronization(&htim6, &sMasterConfig) != HAL_OK)
  {
    Error_Handler();
  }

}

static void MX_TIM8_Init(void)
{

  TIM_Encoder_InitTypeDef sConfig = {0};
  TIM_MasterConfigTypeDef sMasterConfig = {0};

  htim8.Instance = TIM8;
  htim8.Init.Prescaler = 0;
  htim8.Init.CounterMode = TIM_COUNTERMODE_UP;
  htim8.Init.Period = 16383;
  htim8.Init.ClockDivision = TIM_CLOCKDIVISION_DIV1;
  htim8.Init.RepetitionCounter = 0;
  htim8.Init.AutoReloadPreload = TIM_AUTORELOAD_PRELOAD_ENABLE;
  sConfig.EncoderMode = TIM_ENCODERMODE_TI12;
  sConfig.IC1Polarity = TIM_ICPOLARITY_RISING;
  sConfig.IC1Selection = TIM_ICSELECTION_DIRECTTI;
  sConfig.IC1Prescaler = TIM_ICPSC_DIV1;
  sConfig.IC1Filter = 0;
  sConfig.IC2Polarity = TIM_ICPOLARITY_RISING;
  sConfig.IC2Selection = TIM_ICSELECTION_DIRECTTI;
  sConfig.IC2Prescaler = TIM_ICPSC_DIV1;
  sConfig.IC2Filter = 0;
  if (HAL_TIM_Encoder_Init(&htim8, &sConfig) != HAL_OK)
  {
    Error_Handler();
  }
  sMasterConfig.MasterOutputTrigger = TIM_TRGO_RESET;
  sMasterConfig.MasterOutputTrigger2 = TIM_TRGO2_RESET;
  sMasterConfig.MasterSlaveMode = TIM_MASTERSLAVEMODE_DISABLE;
  if (HAL_TIMEx_MasterConfigSynchronization(&htim8, &sMasterConfig) != HAL_OK)
  {
    Error_Handler();
  }

}

static void MX_TIM13_Init(void)
{

  TIM_OC_InitTypeDef sConfigOC = {0};

  htim13.Instance = TIM13;
  htim13.Init.Prescaler = 275-1;
  htim13.Init.CounterMode = TIM_COUNTERMODE_UP;
  htim13.Init.Period = 1000-1;
  htim13.Init.ClockDivision = TIM_CLOCKDIVISION_DIV1;
  htim13.Init.AutoReloadPreload = TIM_AUTORELOAD_PRELOAD_DISABLE;
  if (HAL_TIM_Base_Init(&htim13) != HAL_OK)
  {
    Error_Handler();
  }
  if (HAL_TIM_PWM_Init(&htim13) != HAL_OK)
  {
    Error_Handler();
  }
  sConfigOC.OCMode = TIM_OCMODE_PWM1;
  sConfigOC.Pulse = 500-1;
  sConfigOC.OCPolarity = TIM_OCPOLARITY_HIGH;
  sConfigOC.OCFastMode = TIM_OCFAST_DISABLE;
  if (HAL_TIM_PWM_ConfigChannel(&htim13, &sConfigOC, TIM_CHANNEL_1) != HAL_OK)
  {
    Error_Handler();
  }
  HAL_TIM_MspPostInit(&htim13);

}

static void MX_TIM14_Init(void)
{

  TIM_OC_InitTypeDef sConfigOC = {0};

  htim14.Instance = TIM14;
  htim14.Init.Prescaler = 275-1;
  htim14.Init.CounterMode = TIM_COUNTERMODE_UP;
  htim14.Init.Period = 1000-1;
  htim14.Init.ClockDivision = TIM_CLOCKDIVISION_DIV1;
  htim14.Init.AutoReloadPreload = TIM_AUTORELOAD_PRELOAD_DISABLE;
  if (HAL_TIM_Base_Init(&htim14) != HAL_OK)
  {
    Error_Handler();
  }
  if (HAL_TIM_PWM_Init(&htim14) != HAL_OK)
  {
    Error_Handler();
  }
  sConfigOC.OCMode = TIM_OCMODE_PWM1;
  sConfigOC.Pulse = 500-1;
  sConfigOC.OCPolarity = TIM_OCPOLARITY_HIGH;
  sConfigOC.OCFastMode = TIM_OCFAST_DISABLE;
  if (HAL_TIM_PWM_ConfigChannel(&htim14, &sConfigOC, TIM_CHANNEL_1) != HAL_OK)
  {
    Error_Handler();
  }
  HAL_TIM_MspPostInit(&htim14);

}

static void MX_TIM15_Init(void)
{

  TIM_MasterConfigTypeDef sMasterConfig = {0};
  TIM_OC_InitTypeDef sConfigOC = {0};
  TIM_BreakDeadTimeConfigTypeDef sBreakDeadTimeConfig = {0};

  htim15.Instance = TIM15;
  htim15.Init.Prescaler = 275-1;
  htim15.Init.CounterMode = TIM_COUNTERMODE_UP;
  htim15.Init.Period = 20000-1;
  htim15.Init.ClockDivision = TIM_CLOCKDIVISION_DIV1;
  htim15.Init.RepetitionCounter = 0;
  htim15.Init.AutoReloadPreload = TIM_AUTORELOAD_PRELOAD_DISABLE;
  if (HAL_TIM_PWM_Init(&htim15) != HAL_OK)
  {
    Error_Handler();
  }
  sMasterConfig.MasterOutputTrigger = TIM_TRGO_RESET;
  sMasterConfig.MasterSlaveMode = TIM_MASTERSLAVEMODE_DISABLE;
  if (HAL_TIMEx_MasterConfigSynchronization(&htim15, &sMasterConfig) != HAL_OK)
  {
    Error_Handler();
  }
  sConfigOC.OCMode = TIM_OCMODE_PWM1;
  sConfigOC.Pulse = 2000-1;
  sConfigOC.OCPolarity = TIM_OCPOLARITY_HIGH;
  sConfigOC.OCNPolarity = TIM_OCNPOLARITY_HIGH;
  sConfigOC.OCFastMode = TIM_OCFAST_DISABLE;
  sConfigOC.OCIdleState = TIM_OCIDLESTATE_RESET;
  sConfigOC.OCNIdleState = TIM_OCNIDLESTATE_RESET;
  if (HAL_TIM_PWM_ConfigChannel(&htim15, &sConfigOC, TIM_CHANNEL_1) != HAL_OK)
  {
    Error_Handler();
  }
  sBreakDeadTimeConfig.OffStateRunMode = TIM_OSSR_DISABLE;
  sBreakDeadTimeConfig.OffStateIDLEMode = TIM_OSSI_DISABLE;
  sBreakDeadTimeConfig.LockLevel = TIM_LOCKLEVEL_OFF;
  sBreakDeadTimeConfig.DeadTime = 0;
  sBreakDeadTimeConfig.BreakState = TIM_BREAK_DISABLE;
  sBreakDeadTimeConfig.BreakPolarity = TIM_BREAKPOLARITY_HIGH;
  sBreakDeadTimeConfig.BreakFilter = 0;
  sBreakDeadTimeConfig.AutomaticOutput = TIM_AUTOMATICOUTPUT_DISABLE;
  if (HAL_TIMEx_ConfigBreakDeadTime(&htim15, &sBreakDeadTimeConfig) != HAL_OK)
  {
    Error_Handler();
  }
  HAL_TIM_MspPostInit(&htim15);

}

static void MX_TIM16_Init(void)
{

  TIM_OC_InitTypeDef sConfigOC = {0};
  TIM_BreakDeadTimeConfigTypeDef sBreakDeadTimeConfig = {0};

  htim16.Instance = TIM16;
  htim16.Init.Prescaler = 275-1;
  htim16.Init.CounterMode = TIM_COUNTERMODE_UP;
  htim16.Init.Period = 1000-1;
  htim16.Init.ClockDivision = TIM_CLOCKDIVISION_DIV1;
  htim16.Init.RepetitionCounter = 0;
  htim16.Init.AutoReloadPreload = TIM_AUTORELOAD_PRELOAD_DISABLE;
  if (HAL_TIM_Base_Init(&htim16) != HAL_OK)
  {
    Error_Handler();
  }
  if (HAL_TIM_PWM_Init(&htim16) != HAL_OK)
  {
    Error_Handler();
  }
  sConfigOC.OCMode = TIM_OCMODE_PWM1;
  sConfigOC.Pulse = 500-1;
  sConfigOC.OCPolarity = TIM_OCPOLARITY_HIGH;
  sConfigOC.OCNPolarity = TIM_OCNPOLARITY_HIGH;
  sConfigOC.OCFastMode = TIM_OCFAST_DISABLE;
  sConfigOC.OCIdleState = TIM_OCIDLESTATE_RESET;
  sConfigOC.OCNIdleState = TIM_OCNIDLESTATE_RESET;
  if (HAL_TIM_PWM_ConfigChannel(&htim16, &sConfigOC, TIM_CHANNEL_1) != HAL_OK)
  {
    Error_Handler();
  }
  sBreakDeadTimeConfig.OffStateRunMode = TIM_OSSR_DISABLE;
  sBreakDeadTimeConfig.OffStateIDLEMode = TIM_OSSI_DISABLE;
  sBreakDeadTimeConfig.LockLevel = TIM_LOCKLEVEL_OFF;
  sBreakDeadTimeConfig.DeadTime = 0;
  sBreakDeadTimeConfig.BreakState = TIM_BREAK_DISABLE;
  sBreakDeadTimeConfig.BreakPolarity = TIM_BREAKPOLARITY_HIGH;
  sBreakDeadTimeConfig.BreakFilter = 0;
  sBreakDeadTimeConfig.AutomaticOutput = TIM_AUTOMATICOUTPUT_DISABLE;
  if (HAL_TIMEx_ConfigBreakDeadTime(&htim16, &sBreakDeadTimeConfig) != HAL_OK)
  {
    Error_Handler();
  }
  HAL_TIM_MspPostInit(&htim16);

}

static void MX_TIM17_Init(void)
{

  TIM_OC_InitTypeDef sConfigOC = {0};
  TIM_BreakDeadTimeConfigTypeDef sBreakDeadTimeConfig = {0};

  htim17.Instance = TIM17;
  htim17.Init.Prescaler = 275-1;
  htim17.Init.CounterMode = TIM_COUNTERMODE_UP;
  htim17.Init.Period = 1000-1;
  htim17.Init.ClockDivision = TIM_CLOCKDIVISION_DIV1;
  htim17.Init.RepetitionCounter = 0;
  htim17.Init.AutoReloadPreload = TIM_AUTORELOAD_PRELOAD_DISABLE;
  if (HAL_TIM_Base_Init(&htim17) != HAL_OK)
  {
    Error_Handler();
  }
  if (HAL_TIM_PWM_Init(&htim17) != HAL_OK)
  {
    Error_Handler();
  }
  sConfigOC.OCMode = TIM_OCMODE_PWM1;
  sConfigOC.Pulse = 500-1;
  sConfigOC.OCPolarity = TIM_OCPOLARITY_HIGH;
  sConfigOC.OCNPolarity = TIM_OCNPOLARITY_HIGH;
  sConfigOC.OCFastMode = TIM_OCFAST_DISABLE;
  sConfigOC.OCIdleState = TIM_OCIDLESTATE_RESET;
  sConfigOC.OCNIdleState = TIM_OCNIDLESTATE_RESET;
  if (HAL_TIM_PWM_ConfigChannel(&htim17, &sConfigOC, TIM_CHANNEL_1) != HAL_OK)
  {
    Error_Handler();
  }
  sBreakDeadTimeConfig.OffStateRunMode = TIM_OSSR_DISABLE;
  sBreakDeadTimeConfig.OffStateIDLEMode = TIM_OSSI_DISABLE;
  sBreakDeadTimeConfig.LockLevel = TIM_LOCKLEVEL_OFF;
  sBreakDeadTimeConfig.DeadTime = 0;
  sBreakDeadTimeConfig.BreakState = TIM_BREAK_DISABLE;
  sBreakDeadTimeConfig.BreakPolarity = TIM_BREAKPOLARITY_HIGH;
  sBreakDeadTimeConfig.BreakFilter = 0;
  sBreakDeadTimeConfig.AutomaticOutput = TIM_AUTOMATICOUTPUT_DISABLE;
  if (HAL_TIMEx_ConfigBreakDeadTime(&htim17, &sBreakDeadTimeConfig) != HAL_OK)
  {
    Error_Handler();
  }
  HAL_TIM_MspPostInit(&htim17);

}

static void MX_TIM23_Init(void)
{

  TIM_ClockConfigTypeDef sClockSourceConfig = {0};
  TIM_MasterConfigTypeDef sMasterConfig = {0};

  htim23.Instance = TIM23;
  htim23.Init.Prescaler = 275-1;
  htim23.Init.CounterMode = TIM_COUNTERMODE_UP;
  htim23.Init.Period = 4294967295;
  htim23.Init.ClockDivision = TIM_CLOCKDIVISION_DIV1;
  htim23.Init.AutoReloadPreload = TIM_AUTORELOAD_PRELOAD_DISABLE;
  if (HAL_TIM_Base_Init(&htim23) != HAL_OK)
  {
    Error_Handler();
  }
  sClockSourceConfig.ClockSource = TIM_CLOCKSOURCE_INTERNAL;
  if (HAL_TIM_ConfigClockSource(&htim23, &sClockSourceConfig) != HAL_OK)
  {
    Error_Handler();
  }
  sMasterConfig.MasterOutputTrigger = TIM_TRGO_RESET;
  sMasterConfig.MasterSlaveMode = TIM_MASTERSLAVEMODE_DISABLE;
  if (HAL_TIMEx_MasterConfigSynchronization(&htim23, &sMasterConfig) != HAL_OK)
  {
    Error_Handler();
  }

}

static void MX_TIM24_Init(void)
{

  TIM_ClockConfigTypeDef sClockSourceConfig = {0};
  TIM_MasterConfigTypeDef sMasterConfig = {0};

  htim24.Instance = TIM24;
  htim24.Init.Prescaler = 275-1;
  htim24.Init.CounterMode = TIM_COUNTERMODE_UP;
  htim24.Init.Period = 4294967295;
  htim24.Init.ClockDivision = TIM_CLOCKDIVISION_DIV1;
  htim24.Init.AutoReloadPreload = TIM_AUTORELOAD_PRELOAD_DISABLE;
  if (HAL_TIM_Base_Init(&htim24) != HAL_OK)
  {
    Error_Handler();
  }
  sClockSourceConfig.ClockSource = TIM_CLOCKSOURCE_INTERNAL;
  if (HAL_TIM_ConfigClockSource(&htim24, &sClockSourceConfig) != HAL_OK)
  {
    Error_Handler();
  }
  sMasterConfig.MasterOutputTrigger = TIM_TRGO_RESET;
  sMasterConfig.MasterSlaveMode = TIM_MASTERSLAVEMODE_DISABLE;
  if (HAL_TIMEx_MasterConfigSynchronization(&htim24, &sMasterConfig) != HAL_OK)
  {
    Error_Handler();
  }

}

static void MX_USART1_UART_Init(void)
{

  huart1.Instance = USART1;
  huart1.Init.BaudRate = 2000000;
  huart1.Init.WordLength = UART_WORDLENGTH_8B;
  huart1.Init.StopBits = UART_STOPBITS_1;
  huart1.Init.Parity = UART_PARITY_NONE;
  huart1.Init.Mode = UART_MODE_TX_RX;
  huart1.Init.HwFlowCtl = UART_HWCONTROL_NONE;
  huart1.Init.OverSampling = UART_OVERSAMPLING_16;
  huart1.Init.OneBitSampling = UART_ONE_BIT_SAMPLE_DISABLE;
  huart1.Init.ClockPrescaler = UART_PRESCALER_DIV1;
  huart1.AdvancedInit.AdvFeatureInit = UART_ADVFEATURE_NO_INIT;
  if (HAL_UART_Init(&huart1) != HAL_OK)
  {
    Error_Handler();
  }
  if (HAL_UARTEx_SetTxFifoThreshold(&huart1, UART_TXFIFO_THRESHOLD_1_8) != HAL_OK)
  {
    Error_Handler();
  }
  if (HAL_UARTEx_SetRxFifoThreshold(&huart1, UART_RXFIFO_THRESHOLD_1_8) != HAL_OK)
  {
    Error_Handler();
  }
  if (HAL_UARTEx_DisableFifoMode(&huart1) != HAL_OK)
  {
    Error_Handler();
  }

}

static void MX_USART3_UART_Init(void)
{

  huart3.Instance = USART3;
  huart3.Init.BaudRate = 115200;
  huart3.Init.WordLength = UART_WORDLENGTH_8B;
  huart3.Init.StopBits = UART_STOPBITS_1;
  huart3.Init.Parity = UART_PARITY_NONE;
  huart3.Init.Mode = UART_MODE_TX_RX;
  huart3.Init.HwFlowCtl = UART_HWCONTROL_NONE;
  huart3.Init.OverSampling = UART_OVERSAMPLING_16;
  huart3.Init.OneBitSampling = UART_ONE_BIT_SAMPLE_DISABLE;
  huart3.Init.ClockPrescaler = UART_PRESCALER_DIV1;
  huart3.AdvancedInit.AdvFeatureInit = UART_ADVFEATURE_NO_INIT;
  if (HAL_UART_Init(&huart3) != HAL_OK)
  {
    Error_Handler();
  }
  if (HAL_UARTEx_SetTxFifoThreshold(&huart3, UART_TXFIFO_THRESHOLD_1_8) != HAL_OK)
  {
    Error_Handler();
  }
  if (HAL_UARTEx_SetRxFifoThreshold(&huart3, UART_RXFIFO_THRESHOLD_1_8) != HAL_OK)
  {
    Error_Handler();
  }
  if (HAL_UARTEx_DisableFifoMode(&huart3) != HAL_OK)
  {
    Error_Handler();
  }

}

static void MX_DMA_Init(void)
{

  /* DMA controller clock enable */
  __HAL_RCC_DMA1_CLK_ENABLE();

  /* DMA interrupt init */
  /* DMA1_Stream0_IRQn interrupt configuration */
  HAL_NVIC_SetPriority(DMA1_Stream0_IRQn, 0, 0);
  HAL_NVIC_EnableIRQ(DMA1_Stream0_IRQn);

}

static void MX_GPIO_Init(void)
{
  GPIO_InitTypeDef GPIO_InitStruct = {0};

  /* GPIO Ports Clock Enable */
  __HAL_RCC_GPIOE_CLK_ENABLE();
  __HAL_RCC_GPIOH_CLK_ENABLE();
  __HAL_RCC_GPIOC_CLK_ENABLE();
  __HAL_RCC_GPIOA_CLK_ENABLE();
  __HAL_RCC_GPIOB_CLK_ENABLE();
  __HAL_RCC_GPIOD_CLK_ENABLE();

  /*Configure GPIO pin Output Level */
  HAL_GPIO_WritePin(GPIOE, DIR3_Pin|DIR4_Pin|DIR5_Pin|Output_EN_Pin
                          |EMSW2_Pin|EMSW3_Pin|EMSW4_Pin|EERAM_SS_Pin
                          |EERAM_HOLD_Pin|DIR1_Pin|DIR2_Pin, GPIO_PIN_RESET);

  /*Configure GPIO pin Output Level */
  HAL_GPIO_WritePin(GPIOC, Griper0_Pin|Griper1_Pin|LED2_Pin|LED1_Pin, GPIO_PIN_RESET);

  /*Configure GPIO pin Output Level */
  HAL_GPIO_WritePin(GPIOB, EMSW1_Pin|EN45_Pin|EN123_Pin, GPIO_PIN_RESET);

  /*Configure GPIO pin Output Level */
  HAL_GPIO_WritePin(GPIOD, LED4_Pin|LED3_Pin|SPI3_EN_Pin, GPIO_PIN_RESET);

  /*Configure GPIO pin Output Level */
  HAL_GPIO_WritePin(GPIOD, SPI3_SS6_Pin|SPI3_SS5_Pin|SPI3_SS4_Pin|SPI3_SS3_Pin
                          |SPI3_SS2_Pin|SPI3_SS1_Pin, GPIO_PIN_SET);

  /*Configure GPIO pins : DIR3_Pin DIR4_Pin DIR5_Pin Output_EN_Pin
                           EMSW2_Pin EMSW3_Pin EMSW4_Pin EERAM_SS_Pin
                           EERAM_HOLD_Pin DIR1_Pin DIR2_Pin */
  GPIO_InitStruct.Pin = DIR3_Pin|DIR4_Pin|DIR5_Pin|Output_EN_Pin
                          |EMSW2_Pin|EMSW3_Pin|EMSW4_Pin|EERAM_SS_Pin
                          |EERAM_HOLD_Pin|DIR1_Pin|DIR2_Pin;
  GPIO_InitStruct.Mode = GPIO_MODE_OUTPUT_PP;
  GPIO_InitStruct.Pull = GPIO_NOPULL;
  GPIO_InitStruct.Speed = GPIO_SPEED_FREQ_LOW;
  HAL_GPIO_Init(GPIOE, &GPIO_InitStruct);

  /*Configure GPIO pins : Griper0_Pin Griper1_Pin LED2_Pin LED1_Pin */
  GPIO_InitStruct.Pin = Griper0_Pin|Griper1_Pin|LED2_Pin|LED1_Pin;
  GPIO_InitStruct.Mode = GPIO_MODE_OUTPUT_PP;
  GPIO_InitStruct.Pull = GPIO_NOPULL;
  GPIO_InitStruct.Speed = GPIO_SPEED_FREQ_LOW;
  HAL_GPIO_Init(GPIOC, &GPIO_InitStruct);

  /*Configure GPIO pins : Griper2_Pin EMSW0_Pin */
  GPIO_InitStruct.Pin = Griper2_Pin|EMSW0_Pin;
  GPIO_InitStruct.Mode = GPIO_MODE_IT_RISING;
  GPIO_InitStruct.Pull = GPIO_NOPULL;
  HAL_GPIO_Init(GPIOB, &GPIO_InitStruct);

  /*Configure GPIO pins : EMSW1_Pin EN45_Pin EN123_Pin */
  GPIO_InitStruct.Pin = EMSW1_Pin|EN45_Pin|EN123_Pin;
  GPIO_InitStruct.Mode = GPIO_MODE_OUTPUT_PP;
  GPIO_InitStruct.Pull = GPIO_NOPULL;
  GPIO_InitStruct.Speed = GPIO_SPEED_FREQ_LOW;
  HAL_GPIO_Init(GPIOB, &GPIO_InitStruct);

  /*Configure GPIO pins : LED4_Pin LED3_Pin SPI3_SS6_Pin SPI3_SS5_Pin
                           SPI3_SS4_Pin SPI3_SS3_Pin SPI3_SS2_Pin SPI3_SS1_Pin
                           SPI3_EN_Pin */
  GPIO_InitStruct.Pin = LED4_Pin|LED3_Pin|SPI3_SS6_Pin|SPI3_SS5_Pin
                          |SPI3_SS4_Pin|SPI3_SS3_Pin|SPI3_SS2_Pin|SPI3_SS1_Pin
                          |SPI3_EN_Pin;
  GPIO_InitStruct.Mode = GPIO_MODE_OUTPUT_PP;
  GPIO_InitStruct.Pull = GPIO_NOPULL;
  GPIO_InitStruct.Speed = GPIO_SPEED_FREQ_LOW;
  HAL_GPIO_Init(GPIOD, &GPIO_InitStruct);

  /*Configure GPIO pin : ENC6I_Pin */
  GPIO_InitStruct.Pin = ENC6I_Pin;
  GPIO_InitStruct.Mode = GPIO_MODE_INPUT;
  GPIO_InitStruct.Pull = GPIO_NOPULL;
  HAL_GPIO_Init(ENC6I_GPIO_Port, &GPIO_InitStruct);

}

void Error_Handler(void)
{
  __disable_irq();
  while (1)
  {
  }
}
